VERSION ""

NS_ :

BS_:

BU_: DBG DRIVER IO MOTOR SENSOR

BO_ 100 DRIVER_HEARTBEAT: 1 DRIVER
 SG_ DRIVER_HEARTBEAT_cmd : 0|8@1+ (1,0) [0|0] "" SENSOR,MOTOR

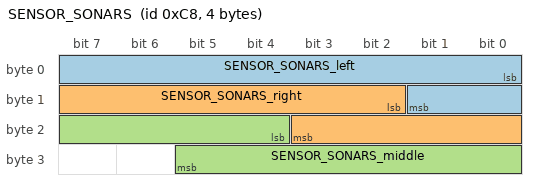
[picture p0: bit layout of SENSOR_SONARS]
BO_ 200 SENSOR_SONARS: 4 SENSOR
 SG_ SENSOR_SONARS_left : 0|10@1+ (1,0) [0|800] "inch" DRIVER
 SG_ SENSOR_SONARS_right : 10|10@1+ (1,0) [0|0] "inch" DRIVER
 SG_ SENSOR_SONARS_middle : 20|10@1+ (1,0) [0|0] "inch" DRIVER

BO_ 300 SENSOR_ACCMTR : 4 SENSOR
 SG_ SENSOR_ACCMTR_x : 0|16@1- (1,0) [0|0] "x-axis" DRIVER
 SG_ SENSOR_ACCMTR_y : 16|16@1- (1,0) [0|0] "y-axis" DRIVER

BO_ 400 SENSOR_BUTTON : 1 SENSOR
 SG_ SENSOR_BUTTON_bool : 0|1@1+ (1,0) [0|0] "" DRIVER

CM_ BU_ DRIVER "The driver controller driving the car";
CM_ BU_ MOTOR "The motor controller of the car";
CM_ BU_ SENSOR "The sensor controller of the car";
CM_ BO_ 100 "Sync message used to synchronize the controllers";
CM_ SG_ 100 DRIVER_HEARTBEAT_cmd "Heartbeat command from the driver";

BA_DEF_ "BusType" STRING ;
BA_DEF_ BO_ "GenMsgCycleTime" INT 0 0;
BA_DEF_ SG_ "FieldType" STRING ;

BA_DEF_DEF_ "BusType" "CAN";
BA_DEF_DEF_ "FieldType" "";
BA_DEF_DEF_ "GenMsgCycleTime" 0;

BA_ "GenMsgCycleTime" BO_ 100 1000;
BA_ "GenMsgCycleTime" BO_ 200 50;
BA_ "FieldType" SG_ 100 DRIVER_HEARTBEAT_cmd "DRIVER_HEARTBEAT_cmd";

VAL_ 100 DRIVER_HEARTBEAT_cmd 2 "DRIVER_HEARTBEAT_cmd_REBOOT" 1 "DRIVER_HEARTBEAT_cmd_SYNC" 0 "DRIVER_HEARTBEAT_cmd_NOOP" ;
